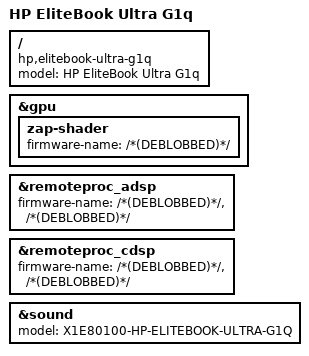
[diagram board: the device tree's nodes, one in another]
// SPDX-License-Identifier: BSD-3-Clause

/dts-v1/;

#include "x1e80100-hp-omnibook-x14.dts"

/ {
	model = "HP EliteBook Ultra G1q";
	compatible = "hp,elitebook-ultra-g1q", "qcom,x1e80100";
};

&gpu {
	zap-shader {
		firmware-name = "/*(DEBLOBBED)*/";
	};
};

&remoteproc_adsp {
	firmware-name = "/*(DEBLOBBED)*/",
			"/*(DEBLOBBED)*/";
};

&remoteproc_cdsp {
	firmware-name = "/*(DEBLOBBED)*/",
			"/*(DEBLOBBED)*/";
};

&sound {
	model = "X1E80100-HP-ELITEBOOK-ULTRA-G1Q";
};
